# ADuCM362 register map
Vendor: Analog Devices Inc.; Series: ADuCM36x; File version: 0.1
CPU: CM3 r2p1, little endian, no MPU, no FPU, 3 interrupt priority bits
Registers are 16-bit, read-write, no defined reset value unless marked. A register's access mark holds for its fields unless they carry their own. Offsets are from the block's base; [hi:lo] are bit positions; {n}, {i} and the like mark numbered series.

## ADI_RESET — Reset
Base 0x40002440
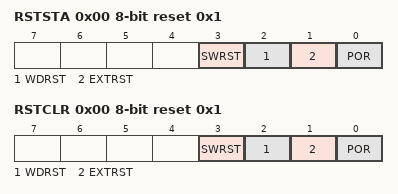
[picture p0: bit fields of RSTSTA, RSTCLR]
0x00 RSTSTA 8-bit ro reset 0x1 (reset mask 0x0) — Reset Status
  [all] fields
    0=CLR; 1=SET
  [3] SWRST — Software reset status bit
  [2] WDRST — Watchdog reset status bit
  [1] EXTRST — External reset status bit
  [0] POR — Power-on reset status bit
0x00 RSTCLR 8-bit wo reset 0x1 (reset mask 0x0) (alternate view of RSTSTA) — Reset Status Clear
  [all] fields
    0=DIS; 1=EN
  [3] SWRST — Software reset status bit
  [2] WDRST — Watchdog reset status bit
  [1] EXTRST — External reset status bit
  [0] POR — Power-on reset status bit

## ADI_INTERRUPT — Interrupts
Base 0x40002420
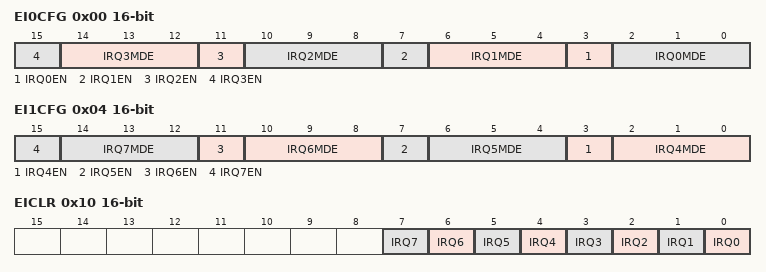
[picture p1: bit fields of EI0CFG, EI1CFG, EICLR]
0x00 EI0CFG — External Interrupt configuration register 0
  [4n+3] IRQ{n}EN (n=0..3) — External Interrupt {n} Enable
    0=DIS; 1=EN
  [14:12] IRQ3MDE — External Interrupt 0 Mode
    0=RISE; 1=FALL; 2=RISEORFALL; 3=HIGHLEVEL; 4=LOWLEVEL
  [10:8] IRQ2MDE — External Interrupt 2 Mode
    0=RISE; 1=FALL; 2=RISEORFALL; 3=HIGHLEVEL; 4=LOWLEVEL
  [6:4] IRQ1MDE — External Interrupt 1 Mode
    0=RISE; 1=FALL; 2=RISEORFALL; 3=HIGHLEVEL; 4=LOWLEVEL
  [2:0] IRQ0MDE — External Interrupt 0 Mode
    0=RISE; 1=FALL; 2=RISEORFALL; 3=HIGHLEVEL; 4=LOWLEVEL
0x04 EI1CFG — External Interrupt configuration register 1
  [4n-13] IRQ{n}EN (n=4..7) — External Interrupt {n} Enable
    0=DIS; 1=EN
  [4n-14:4n-16] IRQ{n}MDE (n=4..7) — External Interrupt {n} Mode
    0=RISE; 1=FALL; 2=RISEORFALL; 3=HIGHLEVEL; 4=LOWLEVEL
0x10 EICLR — External Interrupts Clear register
  [all] fields
    1=CLR
  [n] IRQ{n} (n=0..7) — Clears External interrupt {n} internal flag

## ADI_WDT — Watchdog Timer
Base 0x40002580
0x00 T3LD reset 0x1000 (reset mask 0x0) — Load value.
  [15:0] VALUE range 0x00000000..0x0000FFFF — Current Value
0x04 T3VAL ro reset 0x1000 (reset mask 0x0) — Current count value, read only.
  [15:0] VALUE range 0x00000000..0x0000FFFF — Current Value
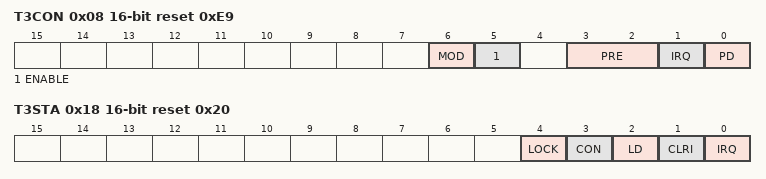
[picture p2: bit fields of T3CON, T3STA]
0x08 T3CON reset 0xE9 (reset mask 0x0) — Control Register
  [6] MOD — Mode
    0=FREERUN; 1=PERIODIC
  [5] ENABLE
    0=DIS; 1=EN
  [3:2] PRE — Prescaler
    0=DIV1; 1=DIV16; 2=DIV256; 3=DIV4096
  [1] IRQ — Timer Interrupt ,
    0=DIS; 1=EN
  [0] PD — Power down clear
    0=DIS; 1=EN
0x0C T3CLRI wo — Clear interrupt, write only.
  [15:0] VALUE — Clear Watchdog
    0xCCCC=CLR
0x18 T3STA ro reset 0x20 (reset mask 0x0) — Status register, read only.
  [all] fields
    0=CLR; 1=SET
  [4] LOCK — Lock status bit
  [3] CON — T3CON write sync in progress
  [2] LD — T3LD write sync in progress
  [1] CLRI — T3CLRI write sync in progress
  [0] IRQ — Interrupt Pending

## ADI_WUT — WakeUp Timer
Base 0x40002500
0x00 T2VAL0 ro — Current count value LSB
  [15:0] VALUE range 0x00000000..0x0000FFFF — Current Value
0x04 T2VAL1 ro — Current count value MSB
  [15:0] VALUE range 0x00000000..0x0000FFFF — Current Value
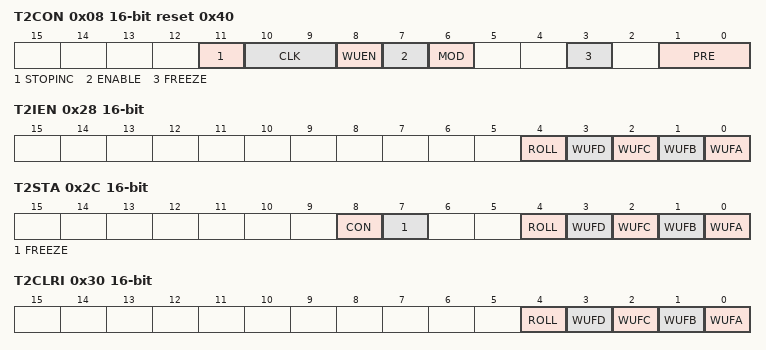
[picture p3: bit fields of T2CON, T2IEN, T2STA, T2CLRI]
0x08 T2CON reset 0x40 (reset mask 0x0) — Control Register
  [11] STOPINC — Stop wake up field A being updated
    0=DIS; 1=EN
  [10:9] CLK — Clock
    0=PCLK; 1=LFXTAL; 2=LFOSC; 3=EXTCLK
  [8] WUEN
    0=DIS; 1=EN
  [7] ENABLE
    0=DIS; 1=EN
  [6] MOD — Mode
    0=PERIODIC; 1=FREERUN
  [3] FREEZE
    0=DIS; 1=EN
  [1:0] PRE — Prescaler
    0=DIV1; 1=DIV16; 2=DIV256; 3=DIV32768
0x0C T2INC reset 0xC8 (reset mask 0x0) — 12-bit register. Wake up field A
  [11:0] VALUE range 0x00000000..0x00000FFF — 12 bit value
0x10 T2WUFB0 reset 0x1FFF (reset mask 0x0) — Wake up field B LSB
  [15:0] VALUE range 0x00000000..0x0000FFFF — Current Value
0x14 T2WUFB1 — Wake up field B MSB
  [15:0] VALUE range 0x00000000..0x0000FFFF — Current Value
0x18 T2WUFC0 reset 0x2FFF (reset mask 0x0) — Wake up field C LSB
  [15:0] VALUE range 0x00000000..0x0000FFFF — Current Value
0x1C T2WUFC1 — Wake up field C MSB
  [15:0] VALUE range 0x00000000..0x0000FFFF — Current Value
0x20 T2WUFD0 reset 0x3FFF (reset mask 0x0) — Wake up field D LSB
  [15:0] VALUE range 0x00000000..0x0000FFFF — Current Value
0x24 T2WUFD1 — Wake up field D MSB
  [15:0] VALUE range 0x00000000..0x0000FFFF — Current Value
0x28 T2IEN — Interrupt enable
  [all] fields
    0=DIS; 1=EN
  [4] ROLL — Enable interrupt on Rollover
  [3] WUFD — Enable interrupt on WUFD
  [2] WUFC — Enable interrupt on WUFC
  [1] WUFB — Enable interrupt on WUFB
  [0] WUFA — Enable interrupt on WUFA
0x2C T2STA ro — Status
  [all] fields
    0=CLR; 1=SET
  [8] CON — Sync
  [7] FREEZE — Timer Value Freeze
  [4] ROLL — Rollover Interrupt
  [3] WUFD — WUFD Interrupt
  [2] WUFC — WUFC Interrupt
  [1] WUFB — WUFB Interrupt
  [0] WUFA — WUFA Interrupt
0x30 T2CLRI wo — Clear interrupts. Write only.
  [all] fields
    1=CLR
  [4] ROLL — Clear interrupt on Rollover
  [3] WUFD — Clear interrupt on WUFD
  [2] WUFC — Clear interrupt on WUFC
  [1] WUFB — Clear interrupt on WUFB
  [0] WUFA — Clear interrupt on WUFA
0x3C T2WUFA0 reset 0x1900 (reset mask 0x0) — Wake up field A LSB.
  [15:0] VALUE range 0x00000000..0x0000FFFF — Current Value
0x40 T2WUFA1 — Wake up field A MSB.
  [15:0] VALUE range 0x00000000..0x0000FFFF — Current Value
